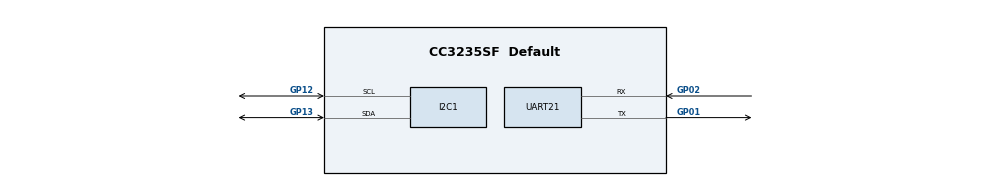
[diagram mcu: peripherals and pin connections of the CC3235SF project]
/**
 * @cliArgs --device "CC3235SF" --package "Default" --part "Default" --rtos "nortos" --product "simplelink_cc32xx_sdk@7.10.00.13"
 * @versions {"tool":"1.20.0+3587"}
 */

/**
 * Import the modules used in this configuration.
 */
const GPIO   = scripting.addModule("/ti/drivers/GPIO");
const I2C    = scripting.addModule("/ti/drivers/I2C");
const I2C1   = I2C.addInstance();
const Power  = scripting.addModule("/ti/drivers/Power");
const Timer  = scripting.addModule("/ti/drivers/Timer", {}, false);
const Timer1 = Timer.addInstance();
const UART2  = scripting.addModule("/ti/drivers/UART2", {}, false);
const UART21 = UART2.addInstance();

/**
 * Write custom configuration values to the imported modules.
 */
I2C1.$name              = "CONFIG_I2C_TMP";
I2C1.i2c.$assign        = "I2C0";
I2C1.i2c.sdaPin.$assign = "GP13";
I2C1.i2c.sclPin.$assign = "GP12";

Power.enableGPIOWakeupLPDS     = false;
Power.enableGPIOWakeupShutdown = false;
Power.parkPins.$name           = "ti_drivers_power_PowerCC32XXPins0";

Timer1.$name         = "CONFIG_TIMER_0";
Timer1.timerType     = "32 Bits";
Timer1.timer.$assign = "Timer0";

UART21.$name                     = "CONFIG_UART2_0";
UART21.uart.txPin.$assign        = "GP01";
UART21.uart.txDmaChannel.$assign = "UDMA_CH9";
UART21.uart.rxPin.$assign        = "GP02";
UART21.uart.rxDmaChannel.$assign = "UDMA_CH8";

/**
 * Pinmux solution for unlocked pins/peripherals. This ensures that minor changes to the automatic solver in a future
 * version of the tool will not impact the pinmux you originally saw.  These lines can be completely deleted in order to
 * re-solve from scratch.
 */
UART21.uart.$suggestSolution = "UART0";
